# STM32H503 register map
File version: 0.3
CPU: CM33 r0p0, little endian, MPU, FPU, 4 interrupt priority bits
Registers are 32-bit, read-write, reset 0x0 unless marked. A register's access mark holds for its fields unless they carry their own. Offsets are from the block's base; [hi:lo] are bit positions; {n}, {i} and the like mark numbered series; <NAME> marks a mode.

## TAMP — Tamper and backup registers
Base 0x44007C00
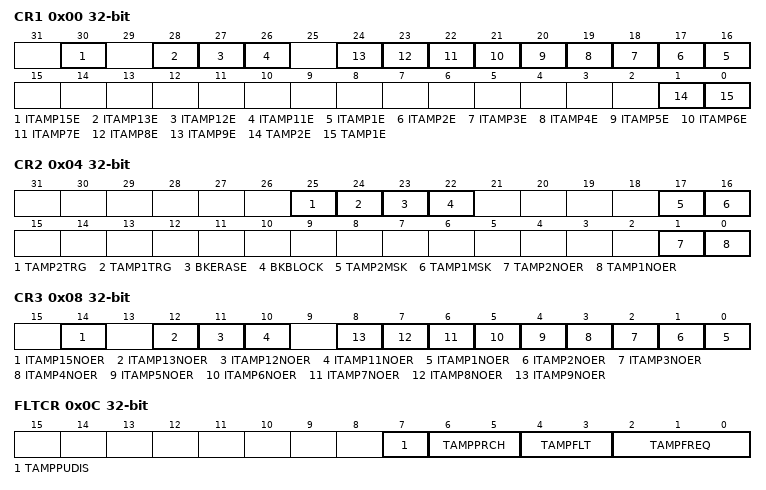
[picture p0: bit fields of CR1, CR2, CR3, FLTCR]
0x00 CR1 — TAMP control register 1
  [30] ITAMP15E — Internal tamper 15 enable
  [28] ITAMP13E — Internal tamper 13 enable
  [27] ITAMP12E — Internal tamper 12 enable
  [26] ITAMP11E — Internal tamper 11 enable
  [n+15] ITAMP{n}E (n=1..9) — Internal tamper {n} enable
  [1] TAMP2E — Tamper detection on TAMP_IN2 enable
  [0] TAMP1E — Tamper detection on TAMP_IN1 enable
0x04 CR2 access per field — TAMP control register 2
  [25] TAMP2TRG rw — Active level for tamper 2 input If TAMPFLT = 00 Tamper 2 input rising edge triggers a tamper detection event. If TAMPFLT = 00 Tamper 2 input falling edge triggers a tamper detection event.
  [24] TAMP1TRG rw — Active level for tamper 1 input If TAMPFLT = 00 Tamper 1 input rising edge triggers a tamper detection event. If TAMPFLT = 00 Tamper 1 input falling edge triggers a tamper detection event.
  [23] BKERASE wo — Backup registers and device secrets<sup>(1)</sup> erase Writing ‘1’ to this bit reset the backup registers and device secrets<sup>(1)</sup>. Writing 0 has no effect. This bit is always read as 0.
  [22] BKBLOCK rw — Backup registers and device secrets<sup>(1)</sup> access blocked
  [17] TAMP2MSK rw — Tamper 2 mask The tamper 2 interrupt must not be enabled when TAMP2MSK is set.
  [16] TAMP1MSK rw — Tamper 1 mask The tamper 1 interrupt must not be enabled when TAMP1MSK is set.
  [1] TAMP2NOER rw — Tamper 2 no erase
  [0] TAMP1NOER rw — Tamper 1 no erase
0x08 CR3 — TAMP control register 3
  [14] ITAMP15NOER — Internal Tamper 15 no erase
  [12] ITAMP13NOER — Internal Tamper 13 no erase
  [11] ITAMP12NOER — Internal Tamper 12 no erase
  [10] ITAMP11NOER — Internal Tamper 11 no erase
  [n-1] ITAMP{n}NOER (n=1..9) — Internal Tamper {n} no erase
0x0C FLTCR — TAMP filter control register
  [7] TAMPPUDIS — TAMP_INx pull-up disable This bit determines if each of the TAMPx pins are precharged before each sample.
  [6:5] TAMPPRCH — TAMP_INx precharge duration These bit determines the duration of time during which the pull-up/is activated before each sample. TAMPPRCH is valid for each of the TAMP_INx inputs.
  [4:3] TAMPFLT — TAMP_INx filter count These bits determines the number of consecutive samples at the specified level (TAMP*TRG) needed to activate a tamper event. TAMPFLT is valid for each of the TAMP_INx inputs.
  [2:0] TAMPFREQ — Tamper sampling frequency Determines the frequency at which each of the TAMP_INx inputs are sampled.
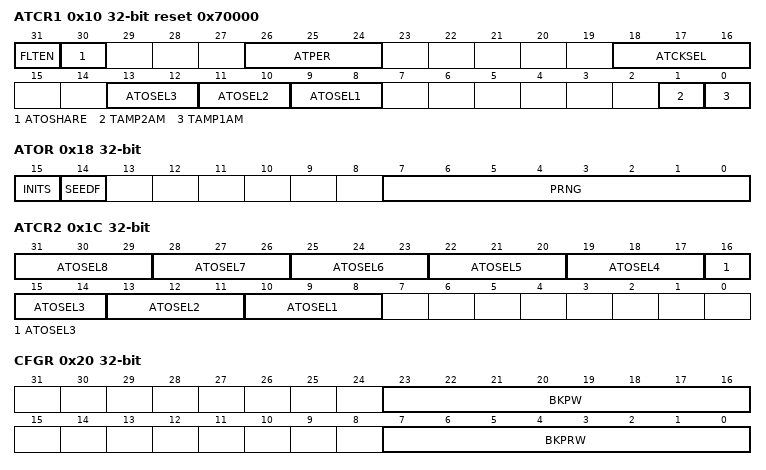
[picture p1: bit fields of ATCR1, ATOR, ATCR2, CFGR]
0x10 ATCR1 reset 0x70000 — TAMP active tamper control register 1
  [31] FLTEN — Active tamper filter enable
  [30] ATOSHARE — Active tamper output sharing TAMP_IN1 is compared with TAMPOUTSEL1 TAMP_IN2 is compared with TAMPOUTSEL2 TAMP_IN3 is compared with TAMPOUTSEL3 TAMP_IN4 is compared with TAMPOUTSEL4 TAMP_IN5 is compared with TAMPOUTSEL5 TAMP_IN6 is compared with TAMPOUTSEL6 TAMP_IN7 is compared with TAMPOUTSEL7 TAMP_IN8 is compared with TAMPOUTSEL8
  [26:24] ATPER — Active tamper output change period The tamper output is changed every CK_ATPER = (2<sup>ATPER </sup>x CK_ATPRE) cycles. Refer to Table 239: Minimum ATPER value.
  [18:16] ATCKSEL — Active tamper RTC asynchronous prescaler clock selection These bits selects the RTC asynchronous prescaler stage output. The selected clock is CK_ATPRE. f<sub>CK_ATPRE</sub> = f<sub>RTCCLK</sub> / 2<sup>ATCKSEL </sup>when (PREDIV_A+1) = 128. ... Note: These bits can be written only when all active tampers are disabled. The write protection remains for up to 1.5 CK_ATPRE cycles after all the active tampers are disable.
  [13:12] ATOSEL3 — Active tamper shared output 3 selection The selected output must be available in the package pinout
  [11:10] ATOSEL2 — Active tamper shared output 2 selection The selected output must be available in the package pinout
  [9:8] ATOSEL1 — Active tamper shared output 1 selection The selected output must be available in the package pinout
  [1] TAMP2AM — Tamper 2 active mode
  [0] TAMP1AM — Tamper 1 active mode
0x14 ATSEEDR wo — TAMP active tamper seed register
  [31:0] SEED — Pseudo-random generator seed value This register must be written four times with 32-bit values to provide the 128-bit seed to the PRNG. Writing to this register automatically sends the seed value to the PRNG.
0x18 ATOR ro — TAMP active tamper output register
  [15] INITS — Active tamper initialization status This flag is set by hardware when the PRNG has absorbed the first 128-bit seed, meaning that the enabled active tampers are functional. This flag is cleared when the active tampers are disabled.
  [14] SEEDF — Seed running flag This flag is set by hardware when a new seed is written in the TAMP_ATSEEDR. It is cleared by hardware when the PRNG has absorbed this new seed, and by system reset. The TAMP APB cock must not be switched off as long as SEEDF is set.
  [7:0] PRNG — Pseudo-random generator value This field provides the values of the PRNG output. Because of potential inconsistencies due to synchronization delays, PRNG must be read at least twice. The read value is correct if it is equal to previous read value.
0x1C ATCR2 — TAMP active tamper control register 2
  [3n+7:3n+5] ATOSEL{n} (n=5..8) — Active tamper shared output {n} selection The selected output must be available in the package pinout.
  [19:17] ATOSEL4 — Active tamper shared output 4 selection The selected output must be available in the package pinout. Bits 18:17 are the mirror of ATOSEL2[1:0] in the TAMP_ATCR1, and so can also be read or written through TAMP_ATCR1.
  [16:14] ATOSEL3 — Active tamper shared output 3 selection The selected output must be available in the package pinout. Bits 15:14 are the mirror of ATOSEL3[1:0] in the TAMP_ATCR1, and so can also be read or written through TAMP_ATCR1.
  [13:11] ATOSEL2 — Active tamper shared output 2 selection The selected output must be available in the package pinout. Bits 12:11 are the mirror of ATOSEL2[1:0] in the TAMP_ATCR1, and so can also be read or written through TAMP_ATCR1.
  [10:8] ATOSEL1 — Active tamper shared output 1 selection The selected output must be available in the package pinout. Bits 9:8 are the mirror of ATOSEL1[1:0] in the TAMP_ATCR1, and so can also be read or written through TAMP_ATCR1.
0x20 CFGR — TAMP configuration register
  [23:16] BKPW — Backup registers write protection offset Protection zone 2 is defined for backup registers from TAMP_BKPyR (y = BKPRW, from 0 to 128) to TAMP_BKPzR (z = BKPW-1, from 0 to 128, BKPW ≥ BKPRW): Protection zone 3 defined for backup registers from TAMP_BKPtR (t = BKPW, from 0 to 127). Note: If BKPW = 0 or if BKPW ≤ BKPRW: there is no protection zone 2. Note: If BKPWPRIV is set, BKPRW[7:0] can be written only in privileged mode.
  [7:0] BKPRW — Backup registers read/write protection offset Protection zone 1 is defined for backup registers from TAMP_BKP0R to TAMP_BKPxR (x = BKPRW-1, from 0 to 128). Note: If BKPRW = 0: there is no protection zone 1. Note: If BKPRWPRIV is set, BKPRW[7:0] can be written only in privileged mode.
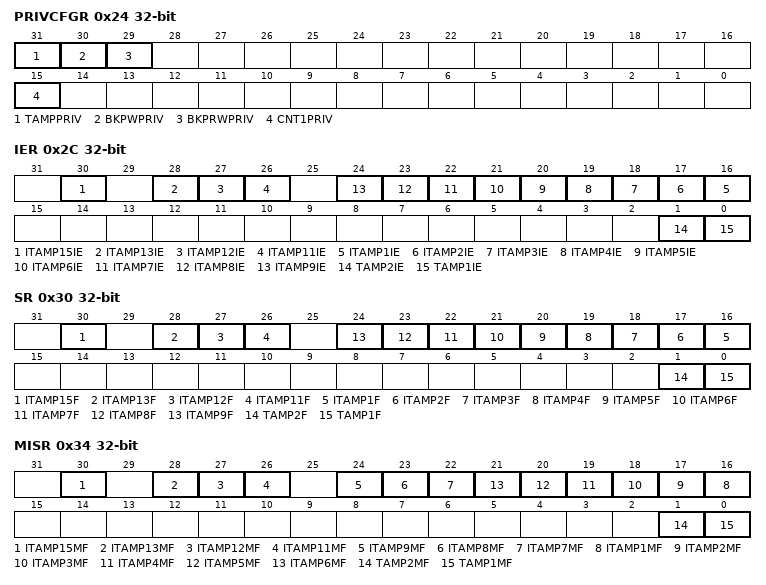
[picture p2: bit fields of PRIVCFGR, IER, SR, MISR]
0x24 PRIVCFGR — TAMP privilege configuration register
  [31] TAMPPRIV — Tamper privilege protection (excluding backup registers) Note: Refer to Section 32.3.6: TAMP privilege protection modes for details on the read protection.
  [30] BKPWPRIV — Backup registers zone 2 privilege protection
  [29] BKPRWPRIV — Backup registers zone 1 privilege protection
  [15] CNT1PRIV — Monotonic counter 1 privilege protection
0x2C IER — TAMP interrupt enable register
  [30] ITAMP15IE — Internal tamper 15 interrupt enable
  [28] ITAMP13IE — Internal tamper 13 interrupt enable
  [27] ITAMP12IE — Internal tamper 12 interrupt enable
  [26] ITAMP11IE — Internal tamper 11 interrupt enable
  [n+15] ITAMP{n}IE (n=1..9) — Internal tamper {n} interrupt enable
  [1] TAMP2IE — Tamper 2 interrupt enable
  [0] TAMP1IE — Tamper 1 interrupt enable
0x30 SR access per field — TAMP status register
  [30] ITAMP15F rw — Internal tamper 15 flag This flag is set by hardware when a tamper detection event is detected on the internal tamper 15.
  [28] ITAMP13F ro — Internal tamper 13 flag This flag is set by hardware when a tamper detection event is detected on the internal tamper 13.
  [27] ITAMP12F ro — Internal tamper 12 flag This flag is set by hardware when a tamper detection event is detected on the internal tamper 12.
  [26] ITAMP11F ro — Internal tamper 11 flag This flag is set by hardware when a tamper detection event is detected on the internal tamper 11.
  [n+15] ITAMP{n}F ro (n=1..9) — Internal tamper {n} flag This flag is set by hardware when a tamper detection event is detected on the internal tamper {n}.
  [1] TAMP2F ro — TAMP2 detection flag This flag is set by hardware when a tamper detection event is detected on the TAMP2 input.
  [0] TAMP1F ro — TAMP1 detection flag This flag is set by hardware when a tamper detection event is detected on the TAMP1 input.
0x34 MISR ro — TAMP masked interrupt status register
  [30] ITAMP15MF — internal tamper 15 interrupt masked flag This flag is set by hardware when the internal tamper 15 interrupt is raised.
  [28] ITAMP13MF — internal tamper 13 interrupt masked flag This flag is set by hardware when the internal tamper 13 interrupt is raised.
  [27] ITAMP12MF — internal tamper 12 interrupt masked flag This flag is set by hardware when the internal tamper 12 interrupt is raised.
  [26] ITAMP11MF — internal tamper 11 interrupt masked flag This flag is set by hardware when the internal tamper 11 interrupt is raised.
  [24] ITAMP9MF — internal tamper 9 interrupt masked flag This flag is set by hardware when the internal tamper 9 interrupt is raised.
  [23] ITAMP8MF — Internal tamper 8 interrupt masked flag This flag is set by hardware when the internal tamper 8 interrupt is raised.
  [22] ITAMP7MF — Internal tamper 7 tamper interrupt masked flag This flag is set by hardware when the internal tamper 7 interrupt is raised.
  [n+15] ITAMP{n}MF (n=1..6) — Internal tamper {n} interrupt masked flag This flag is set by hardware when the internal tamper {n} interrupt is raised.
  [1] TAMP2MF — TAMP2 interrupt masked flag This flag is set by hardware when the tamper 2 interrupt is raised.
  [0] TAMP1MF — TAMP1 interrupt masked flag This flag is set by hardware when the tamper 1 interrupt is raised.
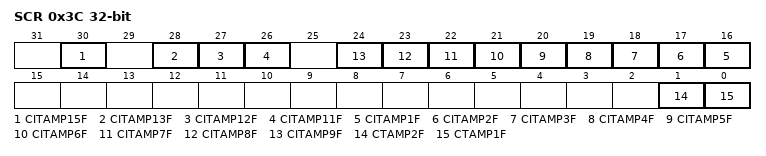
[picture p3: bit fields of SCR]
0x3C SCR wo — TAMP status clear register
  [30] CITAMP15F — Clear ITAMP15 detection flag Writing 1 in this bit clears the ITAMP15F bit in the TAMP_SR register.
  [28] CITAMP13F — Clear ITAMP13 detection flag Writing 1 in this bit clears the ITAMP13F bit in the TAMP_SR register.
  [27] CITAMP12F — Clear ITAMP12 detection flag Writing 1 in this bit clears the ITAMP12F bit in the TAMP_SR register.
  [26] CITAMP11F — Clear ITAMP11 detection flag Writing 1 in this bit clears the ITAMP11F bit in the TAMP_SR register.
  [n+15] CITAMP{n}F (n=1..9) — Clear ITAMP{n} detection flag Writing 1 in this bit clears the ITAMP{n}F bit in the TAMP_SR register.
  [1] CTAMP2F — Clear TAMP2 detection flag Writing 1 in this bit clears the TAMP2F bit in the TAMP_SR register.
  [0] CTAMP1F — Clear TAMP1 detection flag Writing 1 in this bit clears the TAMP1F bit in the TAMP_SR register.
0x40 COUNT1R ro — TAMP monotonic counter 1 register
  [31:0] COUNT — This register is read-only only and is incremented by one when a write access is done to this register. This register cannot roll-over and is frozen when reaching the maximum value.
0x54 ERCFGR — TAMP erase configuration register
  [0] ERCFG0 — Configurable device secrets configuration
{0x100+4i} BKP{i}R (i=0..31) — TAMP backup {i} register
  [31:0] BKP — The application can write or read data to and from these registers. In the default (ERASE) configuration this register is reset on a tamper detection event. It is forced to reset value as long as there is at least one internal or external tamper flag being set.
